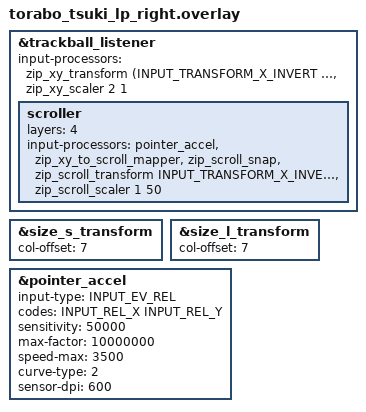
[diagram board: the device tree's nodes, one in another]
#include "torabo_tsuki_lp.dtsi"
#include <input/processors.dtsi>
#include <dt-bindings/zmk/input_transform.h>
#include <scroll-snap.dtsi>
#include <behaviors/input_gestures_accel.dtsi>

&trackball_listener {
    status = "okay";

    // 通常時のカーソル移動
    input-processors = 
        <&zip_xy_transform (INPUT_TRANSFORM_X_INVERT | INPUT_TRANSFORM_Y_INVERT)>,
        <&zip_xy_scaler 2 1>;

    // スクロールモード (レイヤー4)
    scroller {
        layers = <4>;
        input-processors = 
            <&pointer_accel>,  // 加速追加
            <&zip_xy_to_scroll_mapper>,         // スクロール信号に変換
            <&zip_scroll_snap>,                 // スナップ処理
            <&zip_scroll_transform INPUT_TRANSFORM_X_INVERT>,
            <&zip_scroll_scaler 1 50>;          // 速度調整 (1/50)
    };
};

&size_s_transform {
    col-offset = <7>;
};

&size_l_transform {
    col-offset = <7>;
};

&pointer_accel {
    input-type = <INPUT_EV_REL>;
    codes = <INPUT_REL_X INPUT_REL_Y>;
    sensitivity = <50000>;
    max-factor = <10000000>;
    speed-max = <3500>;
    curve-type = <2>;
    sensor-dpi = <600>;
};
